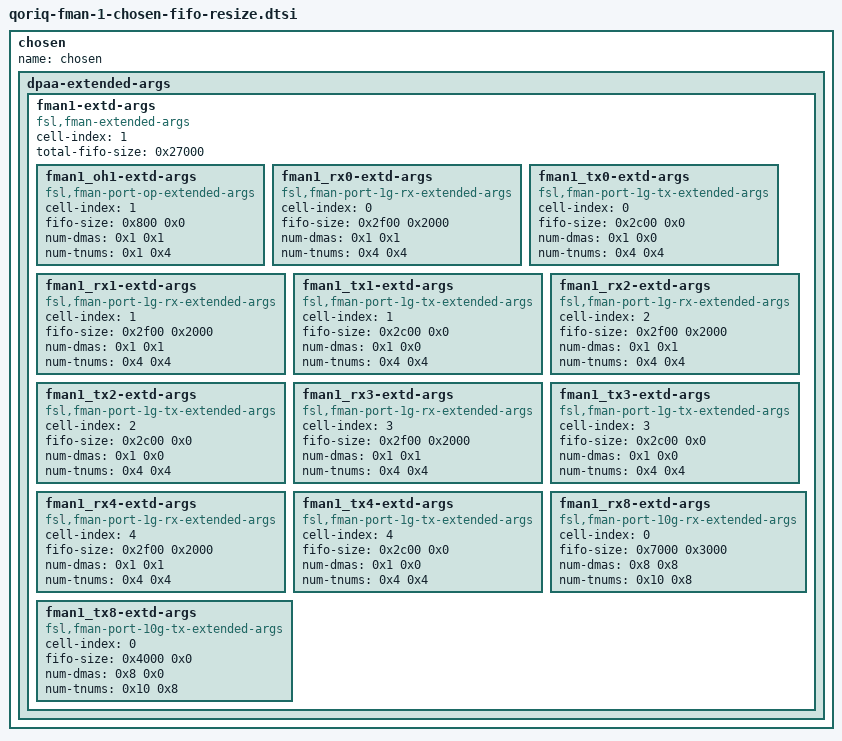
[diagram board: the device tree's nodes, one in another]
/*
 * Qoriq Device Tree Source
 *
 * Copyright 2014 Freescale Semiconductor Inc.
 *
 * Redistribution and use in source and binary forms, with or without
 * modification, are permitted provided that the following conditions are met:
 *     * Redistributions of source code must retain the above copyright
 *       notice, this list of conditions and the following disclaimer.
 *     * Redistributions in binary form must reproduce the above copyright
 *       notice, this list of conditions and the following disclaimer in the
 *       documentation and/or other materials provided with the distribution.
 *     * Neither the name of Freescale Semiconductor nor the
 *       names of its contributors may be used to endorse or promote products
 *       derived from this software without specific prior written permission.
 *
 *
 * ALTERNATIVELY, this software may be distributed under the terms of the
 * GNU General Public License ("GPL") as published by the Free Software
 * Foundation, either version 2 of that License or (at your option) any
 * later version.
 *
 * THIS SOFTWARE IS PROVIDED BY Freescale Semiconductor ``AS IS'' AND ANY
 * EXPRESS OR IMPLIED WARRANTIES, INCLUDING, BUT NOT LIMITED TO, THE IMPLIED
 * WARRANTIES OF MERCHANTABILITY AND FITNESS FOR A PARTICULAR PURPOSE ARE
 * DISCLAIMED. IN NO EVENT SHALL Freescale Semiconductor BE LIABLE FOR ANY
 * DIRECT, INDIRECT, INCIDENTAL, SPECIAL, EXEMPLARY, OR CONSEQUENTIAL DAMAGES
 * (INCLUDING, BUT NOT LIMITED TO, PROCUREMENT OF SUBSTITUTE GOODS OR SERVICES;
 * LOSS OF USE, DATA, OR PROFITS; OR BUSINESS INTERRUPTION) HOWEVER CAUSED AND
 * ON ANY THEORY OF LIABILITY, WHETHER IN CONTRACT, STRICT LIABILITY, OR TORT
 * (INCLUDING NEGLIGENCE OR OTHERWISE) ARISING IN ANY WAY OUT OF THE USE OF THIS
 * SOFTWARE, EVEN IF ADVISED OF THE POSSIBILITY OF SUCH DAMAGE.
 */

chosen {
	name = "chosen";
	dpaa-extended-args {
		fman1-extd-args {
			cell-index = <1>;
			compatible = "fsl,fman-extended-args";
			total-fifo-size = <0x27000>;
			fman1_oh1-extd-args {
				cell-index = <1>;
				compatible = "fsl,fman-port-op-extended-args";
				fifo-size = <0x800 0x0>;
				num-dmas = <0x1 0x1>;
				num-tnums = <0x1 0x4>;
			};
			fman1_rx0-extd-args {
				cell-index = <0>;
				compatible = "fsl,fman-port-1g-rx-extended-args";
				fifo-size = <0x2f00 0x2000>;
				num-dmas = <0x1 0x1>;
				num-tnums = <0x4 0x4>;
			};
			fman1_tx0-extd-args {
				cell-index = <0>;
				compatible = "fsl,fman-port-1g-tx-extended-args";
				fifo-size = <0x2c00 0x0>;
				num-dmas = <0x1 0x0>;
				num-tnums = <0x4 0x4>;
			};
			fman1_rx1-extd-args {
				cell-index = <1>;
				compatible = "fsl,fman-port-1g-rx-extended-args";
				fifo-size = <0x2f00 0x2000>;
				num-dmas = <0x1 0x1>;
				num-tnums = <0x4 0x4>;
			};
			fman1_tx1-extd-args {
				cell-index = <1>;
				compatible = "fsl,fman-port-1g-tx-extended-args";
				fifo-size = <0x2c00 0x0>;
				num-dmas = <0x1 0x0>;
				num-tnums = <0x4 0x4>;
			};
			fman1_rx2-extd-args {
				cell-index = <2>;
				compatible = "fsl,fman-port-1g-rx-extended-args";
				fifo-size = <0x2f00 0x2000>;
				num-dmas = <0x1 0x1>;
				num-tnums = <0x4 0x4>;
			};
			fman1_tx2-extd-args {
				cell-index = <2>;
				compatible = "fsl,fman-port-1g-tx-extended-args";
				fifo-size = <0x2c00 0x0>;
				num-dmas = <0x1 0x0>;
				num-tnums = <0x4 0x4>;
			};
			fman1_rx3-extd-args {
				cell-index = <3>;
				compatible = "fsl,fman-port-1g-rx-extended-args";
				fifo-size = <0x2f00 0x2000>;
				num-dmas = <0x1 0x1>;
				num-tnums = <0x4 0x4>;
			};
			fman1_tx3-extd-args {
				cell-index = <3>;
				compatible = "fsl,fman-port-1g-tx-extended-args";
				fifo-size = <0x2c00 0x0>;
				num-dmas = <0x1 0x0>;
				num-tnums = <0x4 0x4>;
			};
			fman1_rx4-extd-args {
				cell-index = <4>;
				compatible = "fsl,fman-port-1g-rx-extended-args";
				fifo-size = <0x2f00 0x2000>;
				num-dmas = <0x1 0x1>;
				num-tnums = <0x4 0x4>;
			};
			fman1_tx4-extd-args {
				cell-index = <4>;
				compatible = "fsl,fman-port-1g-tx-extended-args";
				fifo-size = <0x2c00 0x0>;
				num-dmas = <0x1 0x0>;
				num-tnums = <0x4 0x4>;
			};
			fman1_rx8-extd-args {
				cell-index = <0>;
				compatible = "fsl,fman-port-10g-rx-extended-args";
				fifo-size = <0x7000 0x3000>;
				num-dmas = <0x8 0x8>;
				num-tnums = <0x10 0x8>;
			};
			fman1_tx8-extd-args {
				cell-index = <0>;
				compatible = "fsl,fman-port-10g-tx-extended-args";
				fifo-size = <0x4000 0x0>;
				num-dmas = <0x8 0x0>;
				num-tnums = <0x10 0x8>;
			};
		};
	};
};
